# RockChip_RK3588 register map
Vendor: RockChip Electronics Co., Ltd.; Series: RK3588; File version: 0.1
Registers are 32-bit, read-write, no defined reset value unless marked. A register's access mark holds for its fields unless they carry their own. Offsets are from the block's base; [hi:lo] are bit positions; {n}, {i} and the like mark numbered series; 'fields as' and 'values as' point back to an identical list.

## PMU (part 1 of 3)
Base 0xFD8D0000
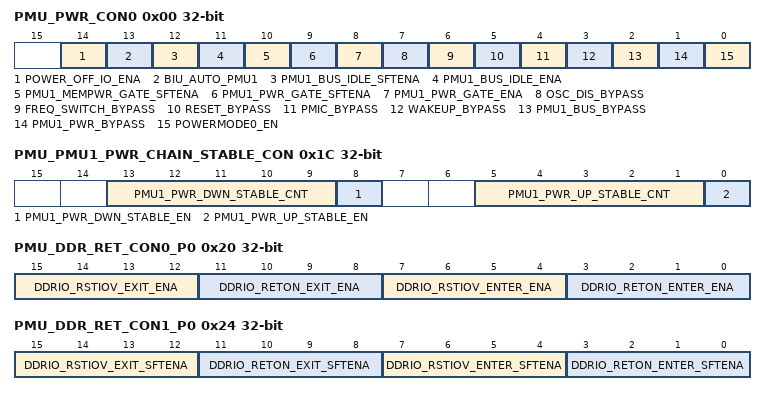
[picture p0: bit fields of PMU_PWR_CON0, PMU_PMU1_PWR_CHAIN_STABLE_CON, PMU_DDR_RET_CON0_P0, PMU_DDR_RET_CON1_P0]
0x00 PMU_PWR_CON0 — PMU power control 0 register
  [all] fields
    0=DISABLE; 1=ENABLE
  [14] POWER_OFF_IO_ENA — Enable VCCIO enter low power mode by hardware.
  [13] BIU_AUTO_PMU1 — When perform idle operation, BIU_PMU1 corresponding clock can be opened or gated automatically.
  [12] PMU1_BUS_IDLE_SFTENA — Enable sending idle request to BIU_PMU1 by software.
  [11] PMU1_BUS_IDLE_ENA — Enable sending idle request to BIU_PMU1 by hardware.
  [10] PMU1_MEMPWR_GATE_SFTENA — Enable power down PD_PMU1's memory by software.
  [9] PMU1_PWR_GATE_SFTENA — Enable power down PD_PMU1 by software.
  [8] PMU1_PWR_GATE_ENA — Enable power down PD_PMU1 by hardware.
  [7] OSC_DIS_BYPASS — Bypass disable oscillator in power mode 0 procedure. If asserted, the oscillator cannot be disabled by FSM during power mode 0 procedure.
  [6] FREQ_SWITCH_BYPASS — Bypass frequency switch stability in power mode 0 procedure. If asserted, clk_pmu cannot be switched to 32KHz clock source during power mode 0 procedure.
  [5] RESET_BYPASS — Bypass wake up reset clear stability in power mode 0 procedure. If asserted, the FSM will enter next state not wait for reset counter, and chip will not be reset.
  [4] PMIC_BYPASS — Bypass waiting for PMIC stability in power mode 0 procedure. If asserted, the FSM will enter next state not wait until PMIC is stable.
  [3] WAKEUP_BYPASS — Bypass waiting for wake up interrupt in power mode 0 procedure. If asserted, the FSM will exit sleep state without waiting for wake up source.
  [2] PMU1_BUS_BYPASS — Bypass BIU_PMU1 idle flow in power mode 0 procedure.
  [1] PMU1_PWR_BYPASS — Bypass PD_PMU1 power gating flow in power mode 0 procedure. If asserted, PD_PMU1 is not power down or power up during power mode 0 procedure.
  [0] POWERMODE0_EN — Power mode 0 enable. When controller enters power mode 0 procedure, this bit is automatically cleared.
0x08 PMU_WAKEUP_INT_CON_P0 — PMU wake up interrupt control register for power mode 0
  [0] WAKEUP_INT_EN — Enable GPIO interrupt as wake up source to exit power mode 0 procedure.
    0=DISABLE; 1=ENABLE
0x0C PMU_WAKEUP_INT_STS_P0 — PMU wake up interrupt status register for power mode 0
  [0] WAKEUP_INT_ST ro — Power mode 0 wake up source status.
    0=INACTIVE; 1=ACTIVE
0x10 PMU_PMIC_STABLE_CNT_P0 — PMIC stable count register for power mode 0
  [19:0] PMIC_STABLE_CNT — PMIC stable count for power mode 0 procedure. Number of clk_pmu used by counter logic.
0x14 PMU_WAKEUP_RST_CLR_CNT_P0 — Wake up reset clear count register for power mode 0
  [19:0] WAKEUP_RST_CLR_CNT — Wake up reset clear count for power mode 0 procedure. Number of clk_pmu used by counter logic.
0x18 PMU_OSC_STABLE_CNT_P0 — Oscillator stable count register for power mode 0
  [19:0] OSC_STABLE_CNT — Oscillator stable count for power mode 0 procedure. Number of clk_pmu used by counter logic.
0x1C PMU_PMU1_PWR_CHAIN_STABLE_CON — PD_PMU1 power chain stable control register
  [13:9] PMU1_PWR_DWN_STABLE_CNT — Stable count for PD_PMU1 power down flow. Number of clk_pmu used by counter logic.
  [8] PMU1_PWR_DWN_STABLE_EN — Enable stable counter between power chains for PD_PMU1 power down flow.
    0=DISABLE; 1=ENABLE
  [5:1] PMU1_PWR_UP_STABLE_CNT — Stable count for PD_PMU1 power up flow. Number of clk_pmu used by counter logic.
  [0] PMU1_PWR_UP_STABLE_EN — Enable stable counter between power chains for PD_PMU1 power up flow.
    0=DISABLE; 1=ENABLE
0x20 PMU_DDR_RET_CON0_P0 — DDR retention control register 0 for power mode 0
  [all] fields
    0=DISABLE; 1=ENABLE
  [15:12] DDRIO_RSTIOV_EXIT_ENA — Enable DDR exits retention mode through RST_IOV by hardware in power mode 0 procedure. Bit[12] used for DDR channel 0. Bit[13] used for DDR channel 1. Bit[14] used for DDR channel 2. Bit[15] used for DDR channel 3.
  [11:8] DDRIO_RETON_EXIT_ENA — Enable DDR exits retention mode through RETON/RETOFF by hardware in power mode 0 procedure. Bit[8] used for DDR channel 0. Bit[9] used for DDR channel 1. Bit[10] used for DDR channel 2. Bit[11] used for DDR channel 3.
  [7:4] DDRIO_RSTIOV_ENTER_ENA — Enable DDR enters retention mode through RST_IOV by hardware in power mode 0 procedure. Bit[4] used for DDR channel 0. Bit[5] used for DDR channel 1. Bit[6] used for DDR channel 2. Bit[7] used for DDR channel 3.
  [3:0] DDRIO_RETON_ENTER_ENA — Enable DDR enters retention mode through RETON/RETOFF by hardware in power mode 0 procedure. Bit[0] used for DDR channel 0. Bit[1] used for DDR channel 1. Bit[2] used for DDR channel 2. Bit[3] used for DDR channel 3.
0x24 PMU_DDR_RET_CON1_P0 — DDR retention control register 1 for power mode 0
  [all] fields
    0=DISABLE; 1=ENABLE
  [15:12] DDRIO_RSTIOV_EXIT_SFTENA — Enable DDR exits retention mode through RST_IOV by software. Bit[12] used for DDR channel 0. Bit[13] used for DDR channel 1. Bit[14] used for DDR channel 2. Bit[15] used for DDR channel 3.
  [11:8] DDRIO_RETON_EXIT_SFTENA — Enable DDR exits retention mode through RETON/RETOFF by software. Bit[8] used for DDR channel 0. Bit[9] used for DDR channel 1. Bit[10] used for DDR channel 2. Bit[11] used for DDR channel 3.
  [7:4] DDRIO_RSTIOV_ENTER_SFTENA — Enable DDR enters retention mode through RST_IOV by software. Bit[4] used for DDR channel 0. Bit[5] used for DDR channel 1. Bit[6] used for DDR channel 2. Bit[7] used for DDR channel 3.
  [3:0] DDRIO_RETON_ENTER_SFTENA — Enable DDR enters retention mode through RETON/RETOFF by software. Bit[0] used for DDR channel 0. Bit[1] used for DDR channel 1. Bit[2] used for DDR channel 2. Bit[3] used for DDR channel 3.
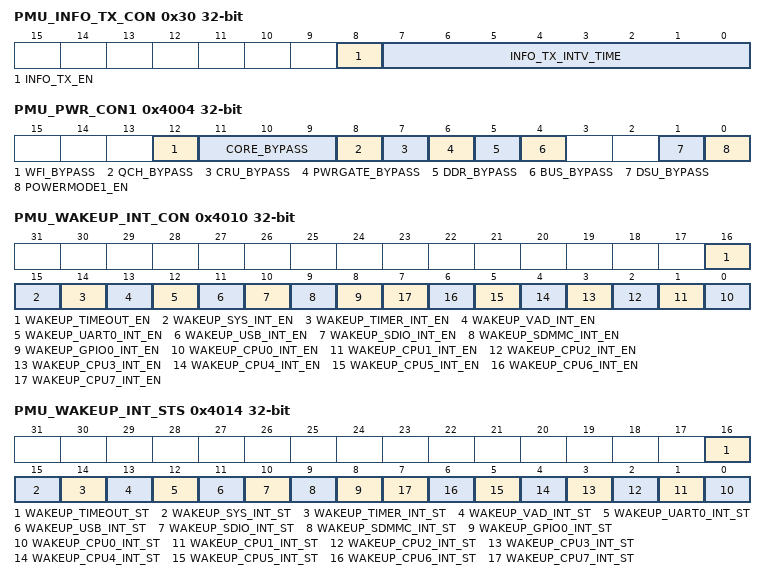
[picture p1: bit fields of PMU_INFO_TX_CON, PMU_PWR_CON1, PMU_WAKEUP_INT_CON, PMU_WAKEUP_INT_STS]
0x30 PMU_INFO_TX_CON — PMU debug information transmit control register
  [8] INFO_TX_EN — Enable PMU debug information transition.
    0=DISABLE; 1=ENABLE
  [7:0] INFO_TX_INTV_TIME — The interval time between the bytes of PMU debug information.
0x4000 PMU_VERSION
  [31:0] VERSION ro
0x4004 PMU_PWR_CON1 — PMU power control 1 register
  [all] fields
    0=DISABLE; 1=ENABLE
  [12] WFI_BYPASS — Bypass WFI in power mode 1 procedure. If asserted, PMU FSM does not need to wait for CPU standbywfi state before entering low power flow.
  [11:9] CORE_BYPASS — Bypass core low power flow in power mode 1 procedure. Bit[9] used to bypass BIGCORE0 low power flow. Bit[10] used to bypass BIGCORE1 low power flow. Bit[11] used to bypass LITDSU low power flow.
  [8] QCH_BYPASS — Bypass power Q-Channel low power flow in power mode 1 procedure. If asserted, PMU_QCHANNEL_PWR_CON cannot take effect for power Q-Channel low power flow. If you want to execute power Q-Channel low power flow, you can program PMU_QCHANNEL_PWR_SFTCON through software flow.
  [7] CRU_BYPASS — Bypass clock and reset low power flow in power mode 1 procedure. If asserted, PMU_CRU_PWR_CON cannot take effect for clock and reset low power flow. If you want to execute clock and reset low power flow, you can program PMU_CRU_PWR_SFTCON through software flow.
  [6] PWRGATE_BYPASS — Bypass power gating flow in power mode 1 procedure. If asserted, PMU_PWR_GATE_CON0/1/2 cannot take effect for power gating flow. If you want to execute power gating flow, you can program PMU_PWR_GATE_SFTCON0/1/2 through software flow.
  [5] DDR_BYPASS — Bypass DDR low power flow in power mode 1 procedure. If asserted, PMU_DDR_CH0/1/2/3_PWR_CON cannot take effect for DDR low power flow. If you want to execute DDR low power flow, you can program PMU_DDR_CH0/1/2/3_PWR_SFTCON through software flow.
  [4] BUS_BYPASS — Bypass BIU idle request in power mode 1 procedure. If asserted, PMU_BIU_IDLE_CON0/1/2 cannot take effect for BIU idle request. If you want to execute BIU idle request, you can program PMU_BIU_IDLE_SFTCON0/1/2 through software flow.
  [1] DSU_BYPASS — Bypass DSU low power flow in power mode 1 procedure.
  [0] POWERMODE1_EN — Power mode 1 enable. When controller enters power mode 1 procedure. It is automatically cleared after PMU enters power mode 1 procedure.
0x4008 PMU_GLB_POWER_STS — PMU global power status register
  [3:0] POWER_STATE ro — PMU1 global power state.
    0=NORMAL (Normal state); 1=CORE_LP (Core low power state); 2=CLUSTER_LP (Cluster low power state); 3=QCH_LP (Q-Channel low power state); 4=BUS_LP (Bus low power state); 5=DDR_LP (DDR low power state); 6=PG_LP (Power gating low power state); 7=CR_LP (Clock and reset low power state); 8=SLEEP (Sleep state); 9=CR_ACTIVE (Clock and reset active state); 10=PG_ACTIVE (Power gating active state); 11=DDR_ACTIVE (DDR active state); 12=BUS_ACTIVE (Bus active state); 13=QCH_ACTIVE (Q-Channel active state); 14=CLUSTER_ACTIVE (Cluster active state); 15=CORE_ACTIVE (Core active state)
0x400C PMU_INT_MASK_CON — PMU interrupt mask control register
  [0] GLB_INT_MASK — Global interrupt mask during DSU sleep state.
    0=UNMASKED (Interrupt is not mask); 1=MASKED (Interrupt is mask)
0x4010 PMU_WAKEUP_INT_CON — PMU wake up interrupt control register
  [all] fields
    0=DISABLE; 1=ENABLE
  [16] WAKEUP_TIMEOUT_EN — Enable PMU wake up timeout as wake up source to exit power mode 1 procedure.
  [15] WAKEUP_SYS_INT_EN — Enable system interrupt as wake up source to exit power mode 1 procedure.
  [14] WAKEUP_TIMER_INT_EN — Enable PMU_TIMER interrupt as wake up source to exit power mode 1 procedure.
  [13] WAKEUP_VAD_INT_EN — Enable VAD interrupt as wake up source to exit power mode 1 procedure.
  [12] WAKEUP_UART0_INT_EN — Enable UART0 interrupt as wake up source to exit power mode 1 procedure.
  [11] WAKEUP_USB_INT_EN — Enable USB detect interrupt as wake up source to exit power mode 1 procedure.
  [10] WAKEUP_SDIO_INT_EN — Enable SDIO interrupt as wake up source to exit power mode 1 procedure.
  [9] WAKEUP_SDMMC_INT_EN — Enable SDMMC detect interrupt as wake up source to exit power mode 1 procedure.
  [8] WAKEUP_GPIO0_INT_EN — Enable GPIO0 interrupt as wake up source to exit power mode 1 procedure.
  [n] WAKEUP_CPU{n}_INT_EN (n=0..7) — Enable CPU{n} interrupt as wake up source to exit power mode 1 procedure.
0x4014 PMU_WAKEUP_INT_STS — PMU wake up interrupt status register
  [all] fields
    0=INACTIVE; 1=ACTIVE
  [16] WAKEUP_TIMEOUT_ST ro — Wake up timeout as wake up source status.
  [15] WAKEUP_SYS_INT_ST ro — System interrupt as wake up source status.
  [14] WAKEUP_TIMER_INT_ST ro — PMU_TIMER interrupt as wake up source status.
  [13] WAKEUP_VAD_INT_ST ro — VAD interrupt as wake up source status.
  [12] WAKEUP_UART0_INT_ST ro — UART0 interrupt as wake up source status.
  [11] WAKEUP_USB_INT_ST ro — USB detect interrupt as wake up source status.
  [10] WAKEUP_SDIO_INT_ST ro — SDIO interrupt as wake up source status.
  [9] WAKEUP_SDMMC_INT_ST ro — SDMMC detect interrupt as wake up source status.
  [8] WAKEUP_GPIO0_INT_ST ro — GPIO0 interrupt as wake up source status.
  [n] WAKEUP_CPU{n}_INT_ST ro (n=0..7) — CPU{n} interrupt as wake up source status.
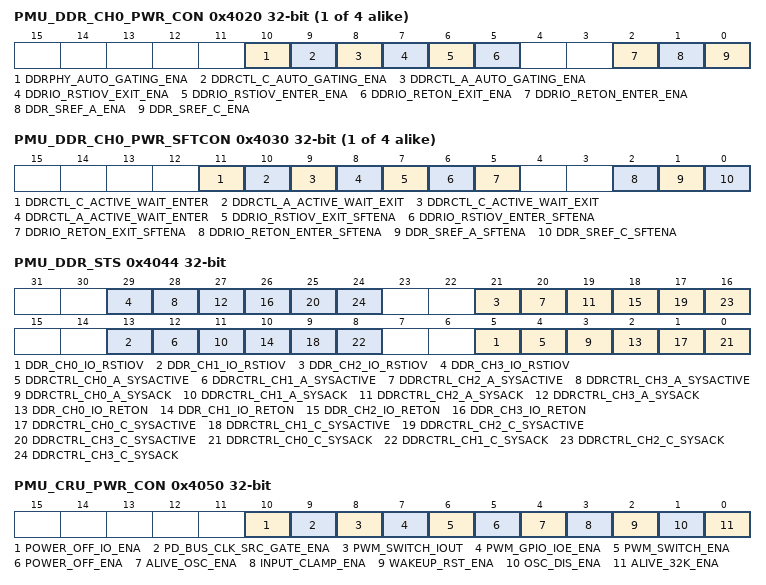
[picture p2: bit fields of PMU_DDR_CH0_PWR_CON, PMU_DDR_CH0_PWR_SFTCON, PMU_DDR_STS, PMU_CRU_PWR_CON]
{0x4020+4i} PMU_DDR_CH{i}_PWR_CON (i=0..3) — DDR channel {i} hardware power control register
  [all] fields
    0=DISABLE; 1=ENABLE
  [10] DDRPHY_AUTO_GATING_ENA — Enable DDRPHY auto clock gating. DDRPHY's clock can be gated when in sleep mode.
  [9] DDRCTL_C_AUTO_GATING_ENA — Enable DDRCTRL's core-clock auto clock gating. Core-clock can be gated when in self-refresh mode.
  [8] DDRCTL_A_AUTO_GATING_ENA — Enable DDRCTRL's AXI-clock auto clock gating. AXI-clock can be gated when in self-refresh mode.
  [7] DDRIO_RSTIOV_EXIT_ENA — Enable DDR exits retention mode through RST_IOV by hardware.
  [6] DDRIO_RSTIOV_ENTER_ENA — Enable DDR enters retention mode through RST_IOV by hardware.
  [5] DDRIO_RETON_EXIT_ENA — Enable DDR exits retention mode through RETON/RETOFF by hardware.
  [2] DDRIO_RETON_ENTER_ENA — Enable DDR enters retention mode through RETON/RETOFF by hardware.
  [1] DDR_SREF_A_ENA — Enable DDR self-refresh mode for AXI-clock domain by hardware.
  [0] DDR_SREF_C_ENA — Enable DDR self-refresh mode for core-clock domain by hardware.
{0x4030+4i} PMU_DDR_CH{i}_PWR_SFTCON (i=0..3) — DDR channel {i} software power control register
  [11] DDRCTL_C_ACTIVE_WAIT_ENTER
    0=NOT_NEED (Not need to wait for ddrctl_c_active low before FSM enter self-refresh state); 1=NEED (Need to wait for ddrctl_c_active low before FSM enter self- refresh state)
  [10] DDRCTL_A_ACTIVE_WAIT_EXIT
    0=NOT_NEED (Not need to wait for ddrctl_a_active high before FSM exit self-refresh state); 1=NEED (Need to wait for ddrctl_a_active high before FSM exit self- refresh state)
  [9] DDRCTL_C_ACTIVE_WAIT_EXIT
    0=NOT_NEED (Not need to wait for ddrctl_c_active high before FSM exit self-refresh state); 1=NEED (Need to wait for ddrctl_c_active high before FSM exit self- refresh state)
  [8] DDRCTL_A_ACTIVE_WAIT_ENTER
    0=NOT_NEED (Not need to wait for ddrctl_a_active low before FSM enter self-refresh state); 1=NEED (Need to wait for ddrctl_a_active low before FSM enter self- refresh state)
  [7] DDRIO_RSTIOV_EXIT_SFTENA — Enable DDR exits retention mode through RST_IOV by software. It is auto cleared after DDR exits retention mode.
    0=DISABLE; 1=ENABLE
  [6] DDRIO_RSTIOV_ENTER_SFTENA — Enable DDR enters retention mode through RST_IOV by software.
    0=DISABLE; 1=ENABLE
  [5] DDRIO_RETON_EXIT_SFTENA — Enable DDR exits retention mode through RETON/RETOFF by software. It is auto cleared after DDR exits retention mode.
    0=DISABLE; 1=ENABLE
  [2] DDRIO_RETON_ENTER_SFTENA — Enable DDR enters retention mode through RETON/RETOFF by software.
    0=DISABLE; 1=ENABLE
  [1] DDR_SREF_A_SFTENA — Enable DDR self-refresh mode for AXI-clock domain by software.
    0=DISABLE; 1=ENABLE
  [0] DDR_SREF_C_SFTENA — Enable DDR self-refresh mode for core-clock domain by software.
    0=DISABLE; 1=ENABLE
0x4040 PMU_DDR_POWER_STS — DDR power state register
  [3:0] DDR_POWER_STATE ro
    0=Normal state; 1=Enter self-refresh mode for AXI-clock state; 2=Enter self-refresh mode core-clock state; 3=Enter retention mode through RETON/RETOFF state; 4=Enter retention mode through RST_IOV state; 5=Sleep state; 6=Exit retention mode through RST_IOV state; 7=Exit retention mode through RETON/RETOFF state; 8=Exit self-refresh mode for core-clock state; 9=Exit self-refresh mode for AXI-clock state Others: Reserved
0x4044 PMU_DDR_STS — DDR state register
  [all] fields
    0=INACTIVE; 1=ACTIVE
  [8n+5] DDR_CH{n}_IO_RSTIOV ro (n=0..3) — DDR RST_IOV state for channel {n}.
  [8n+4] DDRCTRL_CH{n}_A_SYSACTIVE ro (n=0..3) — DDRC AXI clock active for channel {n}.
  [8n+3] DDRCTRL_CH{n}_A_SYSACK ro (n=0..3) — DDRC AXI hardware low-power request acknowledge for channel {n}.
  [8n+2] DDR_CH{n}_IO_RETON ro (n=0..3) — DDR RETON/RETOFF state for channel {n}.
  [8n+1] DDRCTRL_CH{n}_C_SYSACTIVE ro (n=0..3) — DDRC hardware low-power clock active for channel {n}.
  [8n] DDRCTRL_CH{n}_C_SYSACK ro (n=0..3) — DDRC hardware low-power request acknowledge for channel {n}.
0x4050 PMU_CRU_PWR_CON — Clock and reset hardware power control register
  [10] POWER_OFF_IO_ENA — Enable VCCIO enter low power mode by hardware.
    0=DISABLE; 1=ENABLE
  [9] PD_BUS_CLK_SRC_GATE_ENA — Gating BIU_BUS's clock source during clock low power mode.
    0=DISABLE; 1=ENABLE
  [8] PWM_SWITCH_IOUT — PWM output.
    0=DISABLE; 1=ENABLE (It is set 0 for RK3588.)
  [7] PWM_GPIO_IOE_ENA — PWM output enable.
    0=DISABLE; 1=ENABLE (` It is set 0 for RK3588.)
  [6] PWM_SWITCH_ENA — PWM switch enable.
    0=DISABLE; 1=ENABLE (` It is set 0 for RK3588.)
  [5] POWER_OFF_ENA — Enable chip power off by hardware.
    0=DISABLE; 1=ENABLE
  [4] ALIVE_OSC_ENA — Enable clk_pmu/hclk_pmu/pclk_pmu switch to oscillator by hardware. When alive_32k_ena is asserted, this bit is ignored.
    0=DISABLE; 1=ENABLE
  [3] INPUT_CLAMP_ENA — Enable VD_PMU input clamped by hardware.
    0=DISABLE; 1=ENABLE
  [2] WAKEUP_RST_ENA — Enable wake up reset by hardware. If asserted, all registers without reset hold will be reset after chip wake up.
    0=DISABLE; 1=ENABLE
  [1] OSC_DIS_ENA — Disable oscillator by hardware.
    0=ENABLE; 1=DISABLE
  [0] ALIVE_32K_ENA — Enable pclk_pmu and clk_pmu switch to 32KHz clock by hardware.
    0=DISABLE; 1=ENABLE
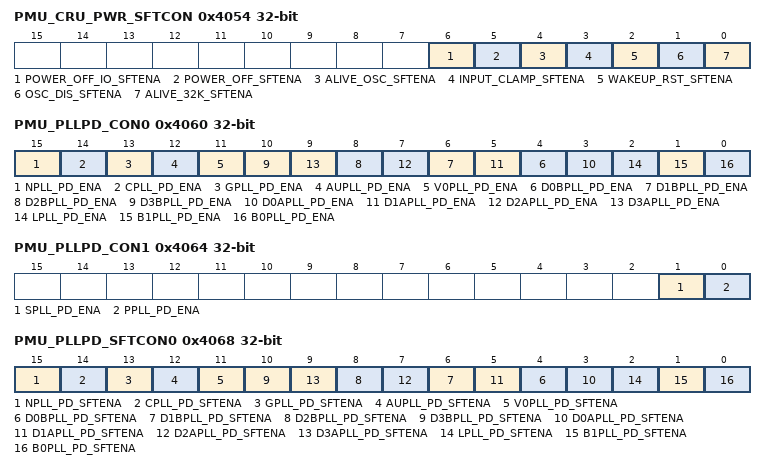
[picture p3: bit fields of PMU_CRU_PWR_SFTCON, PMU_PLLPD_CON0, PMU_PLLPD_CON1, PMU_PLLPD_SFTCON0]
0x4054 PMU_CRU_PWR_SFTCON — Clock and reset software power control register
  [6] POWER_OFF_IO_SFTENA — Enable VCCIO enter low power mode by software.
    0=DISABLE; 1=ENABLE
  [5] POWER_OFF_SFTENA — Enable chip power off by software.
    0=DISABLE; 1=ENABLE
  [4] ALIVE_OSC_SFTENA — Enable clk_pmu/hclk_pmu/pclk_pmu switch to oscillator by software. When alive_32k_ena is asserted, this bit is ignored.
    0=DISABLE; 1=ENABLE
  [3] INPUT_CLAMP_SFTENA — Enable VD_PMU input clamp by software.
    0=DISABLE; 1=ENABLE
  [2] WAKEUP_RST_SFTENA — Enable wake up reset by software. If asserted, all digital except IP with reset hold will be reset.
    0=DISABLE; 1=ENABLE
  [1] OSC_DIS_SFTENA — Disable oscillator by software.
    0=ENABLE; 1=DISABLE
  [0] ALIVE_32K_SFTENA — Enable pclk_pmu and clk_pmu switch to 32KHz clock by software.
    0=DISABLE; 1=ENABLE
0x4058 PMU_CRU_POWER_STS — Clock and reset power state register
  [3:0] CRU_POWER_STATE ro — Clock and reset power state.
    0=Normal state; 1=Clock low frequency state; 2=PLL power down state; 3=Input clamp state; 4=Oscillator disable state; 5=Sleep state; 6=Wake up state; 7=Input clamp release state; 8=Oscillator enable state; 9=Clock high frequency state; 10=Wake up reset clear state; 12=PLL power up state Others: Reserved
0x4060 PMU_PLLPD_CON0 — PLL hardware power control register 0
  [all] fields
    0=DISABLE; 1=ENABLE
  [15] NPLL_PD_ENA — Enable power down NPLL by hardware.
  [14] CPLL_PD_ENA — Enable power down CPLL by hardware.
  [13] GPLL_PD_ENA — Enable power down GPLL by hardware.
  [12] AUPLL_PD_ENA — Enable power down AUPLL by hardware.
  [11] V0PLL_PD_ENA — Enable power down V0PLL by hardware.
  [2n+4] D{n}BPLL_PD_ENA (n=0..3) — Enable power down D{n}BPLL by hardware.
  [2n+3] D{n}APLL_PD_ENA (n=0..3) — Enable power down D{n}APLL by hardware.
  [2] LPLL_PD_ENA — Enable power down LPLL by hardware.
  [1] B1PLL_PD_ENA — Enable power down B1PLL by hardware.
  [0] B0PLL_PD_ENA — Enable power down B0PLL by hardware.
0x4064 PMU_PLLPD_CON1 — PLL hardware power control register 1
  [1] SPLL_PD_ENA — Enable power down SPLL by hardware.
    0=DISABLE; 1=ENABLE
  [0] PPLL_PD_ENA — Enable power down PPLL by hardware.
    0=DISABLE; 1=ENABLE
0x4068 PMU_PLLPD_SFTCON0 — PLL software power control register 0
  [all] fields
    0=DISABLE; 1=ENABLE
  [15] NPLL_PD_SFTENA — Enable power down NPLL by software.
  [14] CPLL_PD_SFTENA — Enable power down CPLL by software.
  [13] GPLL_PD_SFTENA — Enable power down GPLL by software.
  [12] AUPLL_PD_SFTENA — Enable power down AUPLL by software.
  [11] V0PLL_PD_SFTENA — Enable power down V0PLL by software.
  [2n+4] D{n}BPLL_PD_SFTENA (n=0..3) — Enable power down D{n}BPLL by software.
  [2n+3] D{n}APLL_PD_SFTENA (n=0..3) — Enable power down D{n}APLL by software.
  [2] LPLL_PD_SFTENA — Enable power down LPLL by software.
  [1] B1PLL_PD_SFTENA — Enable power down B1PLL by software.
  [0] B0PLL_PD_SFTENA — Enable power down B0PLL by software.
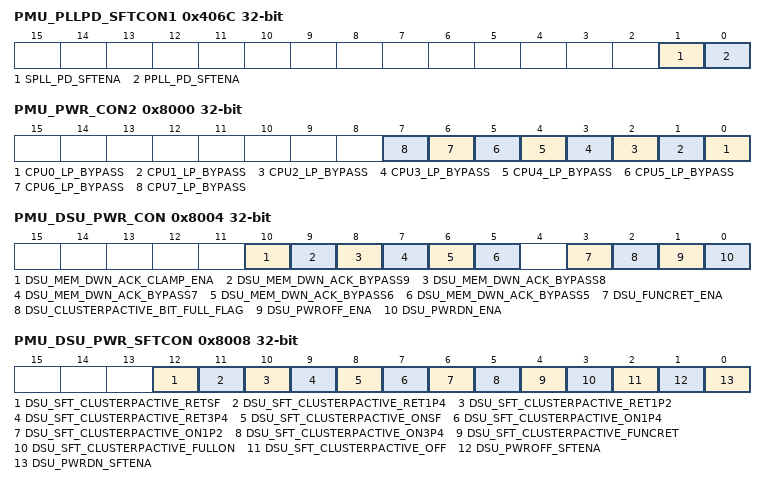
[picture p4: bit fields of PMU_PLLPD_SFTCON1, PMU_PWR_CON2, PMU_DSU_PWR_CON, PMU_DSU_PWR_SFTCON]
0x406C PMU_PLLPD_SFTCON1 — PLL software power control register 1
  [1] SPLL_PD_SFTENA — Enable power down SPLL by software.
    0=DISABLE; 1=ENABLE
  [0] PPLL_PD_SFTENA — Enable power down PPLL by software.
    0=DISABLE; 1=ENABLE
0x4080 PMU_PMIC_STABLE_CNT — PMIC stable count register
  [19:0] PMIC_STABLE_CNT — PMIC stable count for mode 1 procedure. Number of clk_pmu used by counter logic.
0x4084 PMU_OSC_STABLE_CNT — Oscillator stable count register
  [19:0] OSC_STABLE_CNT — Oscillator stable count for mode 1 procedure. Number of clk_pmu used by counter logic.
0x4088 PMU_WAKEUP_RST_CLR_ CNT — Wake up reset clear count register
  [19:0] WAKEUP_RST_CLR_CNT — Wake up reset clear count for mode 1 procedure. Number of clk_pmu used by counter logic.
0x408C PMU_PLL_LOCK_CNT — PLL lock count register
  [19:0] PLL_LOCK_CNT — Count for PLL from power up to lock. Number of clk_pmu used by counter logic.
0x4094 PMU_WAKEUP_TIMEOUT_ CNT — PMU wake up timeout count register
  [19:0] WAKEUP_TIMEOUT_CNT — Wake up timeout count. Number of clk_pmu used by counter logic.
0x4098 PMU_PWM_SWITCH_CNT — PWM switch stable count register
  [19:0] PWM_SWITCH_CNT — PWM switch count. Number of clk_pmu used by counter logic.
{0x4100+4i} PMU_SYS_REG{i} (i=0..7) — PMU system register {i}. It cannot be reset by software.
0x8000 PMU_PWR_CON2 — PMU hardware power control 2 register
  [all] fields
    0=DISABLE; 1=ENABLE
  [n] CPU{n}_LP_BYPASS (n=0..7) — Bypass CPU{n} low power flow.
0x8004 PMU_DSU_PWR_CON — DSU hardware power control register
  [10] DSU_MEM_DWN_ACK_CLAMP_ENA — Enable clamp for VD_DSU memory power down acknowledge. This bit should be set to 1 if dsu_pwroff_ena=1 and VD_DSU will be power off.
    0=DISABLE; 1=ENABLE
  [9] DSU_MEM_DWN_ACK_BYPASS9 — used to bypass other memory power down acknowledge. If memory is power down before DSU enter power down mode, you should set relative bypass bit high.
    0=DISABLE; 1=ENABLE
  [8] DSU_MEM_DWN_ACK_BYPASS8 — used to bypass "L3 Tag ways 8~11, L3 Data portion 1 RAMs" memory power down acknowledge.
    0=DISABLE; 1=ENABLE
  [7] DSU_MEM_DWN_ACK_BYPASS7 — used to bypass "L3 Tag ways 4~7" memory power down acknowledge.
    0=DISABLE; 1=ENABLE
  [6] DSU_MEM_DWN_ACK_BYPASS6 — used to bypass "L3 Tag ways 0~3, L3 Data portion 0, and L3 Victim RAMs" memory power down acknowledge.
    0=DISABLE; 1=ENABLE
  [5] DSU_MEM_DWN_ACK_BYPASS5 — used to bypass "Snoop filter and LTDB RAMs" memory power down acknowledge.
    0=DISABLE; 1=ENABLE
  [3] DSU_FUNCRET_ENA — Enable DSU FUNC_RET mode by hardware.
    0=DISABLE; 1=ENABLE
  [2] DSU_CLUSTERPACTIVE_BIT_FULL_FLAG — CLUSTERPACTIVE bit full flag. If DSU power mode wants to transfer from any mode to FULL ON or FULL FUNC_RET, this bit should be set to 1. Otherwise, this bit should be set to 0.
  [1] DSU_PWROFF_ENA — Enable VD_LITDSU power off by hardware. If you just power down VD_LITDSU memory but not power off VD_LITDSU, this bit should be set to 0. If you want to power off VD_LITDSU by hardware, this bit should be set to 1.
    0=DISABLE; 1=ENABLE
  [0] DSU_PWRDN_ENA — Enable VD_LITDSU power down by hardware.
    0=DISABLE; 1=ENABLE
0x8008 PMU_DSU_PWR_SFTCON — DSU software power control register
  [12] DSU_SFT_CLUSTERPACTIVE_RETSF — CLUSTERPACTIVE bit generated by software when requested mode is SFONLY FUNC_RET mode. High active. It is auto cleared when CLUSTERPREQ is active. It is used when DSU power mode transition is controlled by software.
    1=ACTIVE
  [11] DSU_SFT_CLUSTERPACTIVE_RET1P4 — CLUSTERPACTIVE bit generated by software when requested mode is 1/4 FUNC_RET mode. High active. It is auto cleared when CLUSTERPREQ is active. It is used when DSU power mode transition is controlled by software.
    1=ACTIVE
  [10] DSU_SFT_CLUSTERPACTIVE_RET1P2 — CLUSTERPACTIVE bit generated by software when requested mode is 1/2 FUNC_RET mode. High active. It is auto cleared when CLUSTERPREQ is active. It is used when DSU power mode transition is controlled by software.
    1=ACTIVE
  [9] DSU_SFT_CLUSTERPACTIVE_RET3P4 — CLUSTERPACTIVE bit generated by software when requested mode is 3/4 FUNC_RET mode. High active. It is auto cleared when CLUSTERPREQ is active. It is used when DSU power mode transition is controlled by software.
    1=ACTIVE
  [8] DSU_SFT_CLUSTERPACTIVE_ONSF — CLUSTERPACTIVE bit generated by software when requested mode is SFONLY ON mode. High active. It is auto cleared when CLUSTERPREQ is active. It is used when DSU power mode transition is controlled by software.
    1=ACTIVE
  [7] DSU_SFT_CLUSTERPACTIVE_ON1P4 — CLUSTERPACTIVE bit generated by software when requested mode is 1/4 ON mode. High active. It is auto cleared when CLUSTERPREQ is active. It is used when DSU power mode transition is controlled by software.
    1=ACTIVE
  [6] DSU_SFT_CLUSTERPACTIVE_ON1P2 — CLUSTERPACTIVE bit generated by software when requested mode is 1/2 ON mode. High active. It is auto cleared when CLUSTERPREQ is active. It is used when DSU power mode transition is controlled by software.
    1=ACTIVE
  [5] DSU_SFT_CLUSTERPACTIVE_ON3P4 — CLUSTERPACTIVE bit generated by software when requested mode is 3/4 ON mode. High active. It is auto cleared when CLUSTERPREQ is active. It is used when DSU power mode transition is controlled by software.
    1=ACTIVE
  [4] DSU_SFT_CLUSTERPACTIVE_FUNCRET — CLUSTERPACTIVE bit generated by software when requested mode is FUNC_RET mode. High active. It is auto cleared when CLUSTERPREQ is active. It is used when DSU power mode transition is controlled by software.
    1=ACTIVE
  [3] DSU_SFT_CLUSTERPACTIVE_FULLON — CLUSTERPACTIVE bit generated by software when requested mode is FULL ON mode. High active. It is auto cleared when CLUSTERPREQ is active. It is used when DSU power mode transition is controlled by software.
    1=ACTIVE
  [2] DSU_SFT_CLUSTERPACTIVE_OFF — CLUSTERPACTIVE bit generated by software when requested mode is OFF mode. High active. It is auto cleared when CLUSTERPREQ is active. It is used when DSU power mode transition is controlled by software.
    1=ACTIVE
  [1] DSU_PWROFF_SFTENA — Enable VD_LITDSU power off by software.
    0=DISABLE; 1=ENABLE
  [0] DSU_PWRDN_SFTENA — Enable VD_LITDSU power down by software.
    0=DISABLE; 1=ENABLE
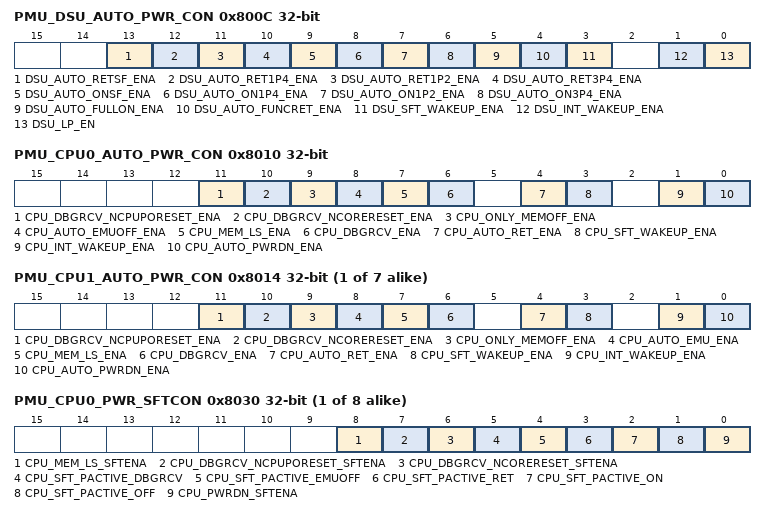
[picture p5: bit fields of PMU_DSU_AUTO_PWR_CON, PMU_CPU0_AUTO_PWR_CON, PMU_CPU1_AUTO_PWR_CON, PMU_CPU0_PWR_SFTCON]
0x800C PMU_DSU_AUTO_PWR_CON — DSU automatic power control register
  [13] DSU_AUTO_RETSF_ENA — Enable DSU enters SFONLY FUNC_RET mode automatically.
    0=DISABLE; 1=ENABLE
  [12] DSU_AUTO_RET1P4_ENA — Enable DSU enters 1/4 FUNC_RET mode automatically.
    0=DISABLE; 1=ENABLE
  [11] DSU_AUTO_RET1P2_ENA — Enable DSU enters 1/2 FUNC_RET mode automatically.
    0=DISABLE; 1=ENABLE
  [10] DSU_AUTO_RET3P4_ENA — Enable DSU enters 3/4 FUNC_RET mode automatically.
    0=DISABLE; 1=ENABLE
  [9] DSU_AUTO_ONSF_ENA — Enable DSU enters SFONLY ON mode automatically.
    0=DISABLE; 1=ENABLE
  [8] DSU_AUTO_ON1P4_ENA — Enable DSU enters 1/4 ON mode automatically.
    0=DISABLE; 1=ENABLE
  [7] DSU_AUTO_ON1P2_ENA — Enable DSU enters 1/2 ON mode automatically.
    0=DISABLE; 1=ENABLE
  [6] DSU_AUTO_ON3P4_ENA — Enable DSU enters 3/4 ON mode automatically.
    0=DISABLE; 1=ENABLE
  [5] DSU_AUTO_FULLON_ENA — Enable DSU enters FULL ON mode automatically.
    0=DISABLE; 1=ENABLE
  [4] DSU_AUTO_FUNCRET_ENA — Enable DSU enters FUNC_RET mode automatically.
    0=DISABLE; 1=ENABLE
  [3] DSU_SFT_WAKEUP_ENA — Enable VD_LITDSU wake up by software.
    0=INACTIVE (Wake up source inactive); 1=ACTIVE (Wake up source active)
  [1] DSU_INT_WAKEUP_ENA — Enable interrupt as VD_LITDSU wake up source.
    0=DISABLE; 1=ENABLE
  [0] DSU_LP_EN — Enable VD_LITDSU low power mode.
    0=DISABLE; 1=ENABLE
0x8010 PMU_CPU0_AUTO_PWR_CON — CPU0 automatic power control register
  [11] CPU_DBGRCV_NCPUPORESET_ENA — Enable CPU enters cold reset by assert ncpureset when CPU in debug recovery mode by hardware.
    0=DISABLE; 1=ENABLE
  [10] CPU_DBGRCV_NCORERESET_ENA — Enable CPU enters warm reset by assert ncorereset when CPU in debug recovery mode by hardware.
    0=DISABLE; 1=ENABLE
  [9] CPU_ONLY_MEMOFF_ENA — Enable only power down CPU memory. i.e., just power down memory, but not other digital logic when CPU in OFF mode.
    0=DISABLE; 1=ENABLE
  [8] CPU_AUTO_EMUOFF_ENA — Enable CPU emulated off mode by hardware.
    0=DISABLE; 1=ENABLE
  [7] CPU_MEM_LS_ENA — Enable CPU memory light sleep mode by hardware.
    0=DISABLE; 1=ENABLE
  [6] CPU_DBGRCV_ENA — Enable CPU debug recovery mode by hardware. It is auto cleared when FSM enters debug recovery state.
    0=DISABLE; 1=ENABLE
  [4] CPU_AUTO_RET_ENA — Enable CPU retention mode by hardware.
    0=DISABLE; 1=ENABLE
  [3] CPU_SFT_WAKEUP_ENA — Enable CPU wake up by software.
    values as PMU_DSU_AUTO_PWR_CON.DSU_SFT_WAKEUP_ENA
  [1] CPU_INT_WAKEUP_ENA — Enable interrupt as CPU wake up source.
    0=DISABLE; 1=ENABLE
  [0] CPU_AUTO_PWRDN_ENA — Enable CPU power down automatically.
    0=DISABLE; 1=ENABLE
{0x8010+4i} PMU_CPU{i}_AUTO_PWR_CON (i=1..7) — CPU{i} automatic power control register
  [11] CPU_DBGRCV_NCPUPORESET_ENA — Enable CPU enters cold reset by assert ncpureset when CPU in debug recovery mode by hardware.
    0=DISABLE; 1=ENABLE
  [10] CPU_DBGRCV_NCORERESET_ENA — Enable CPU enters warm reset by assert ncorereset when CPU in debug recovery mode by hardware.
    0=DISABLE; 1=ENABLE
  [9] CPU_ONLY_MEMOFF_ENA — Enable only power down CPU memory. i.e., just power down memory, but not other digital logic when CPU in OFF mode.
    0=DISABLE; 1=ENABLE
  [8] CPU_AUTO_EMU_ENA — Enable CPU emulated off mode by hardware.
    0=DISABLE; 1=ENABLE
  [7] CPU_MEM_LS_ENA — Enable CPU memory light sleep mode by hardware.
    0=DISABLE; 1=ENABLE
  [6] CPU_DBGRCV_ENA — Enable CPU debug recovery mode by hardware. It is auto cleared when FSM enters debug recovery state.
    0=DISABLE; 1=ENABLE
  [4] CPU_AUTO_RET_ENA — Enable CPU retention mode by hardware.
    0=DISABLE; 1=ENABLE
  [3] CPU_SFT_WAKEUP_ENA — Enable CPU wake up by software.
    values as PMU_DSU_AUTO_PWR_CON.DSU_SFT_WAKEUP_ENA
  [1] CPU_INT_WAKEUP_ENA — Enable interrupt as CPU wake up source.
    0=DISABLE; 1=ENABLE
  [0] CPU_AUTO_PWRDN_ENA — Enable CPU power down automatically.
    0=DISABLE; 1=ENABLE
{0x8030+4i} PMU_CPU{i}_PWR_SFTCON (i=0..7) — CPU{i} software power control register
  [8] CPU_MEM_LS_SFTENA — Enable CPU memory light sleep mode by software.
    0=DISABLE; 1=ENABLE
  [7] CPU_DBGRCV_NCPUPORESET_SFTENA — Enable CPU enters cold reset by assert ncpureset when CPU in debug recovery mode by software.
    0=ENABLE; 1=DISABLE
  [6] CPU_DBGRCV_NCORERESET_SFTENA — Enable CPU enters warm reset by assert ncorereset when CPU in debug recovery mode by software.
    0=ENABLE; 1=DISABLE
  [5] CPU_SFT_PACTIVE_DBGRCV — PACTIVE bit generated by software when requested mode is debug recovery mode. High active. It is auto cleared when PREQ is active. It is used when CPU power mode transition is controlled by software.
    1=ACTIVE
  [4] CPU_SFT_PACTIVE_EMUOFF — PACTIVE bit generated by software when requested mode is emulated off mode. High active. It is auto cleared when PREQ is active. It is used when CPU power mode transition is controlled by software.
    1=ACTIVE
  [3] CPU_SFT_PACTIVE_RET — PACTIVE bit generated by software when requested mode is retention mode. High active. It is auto cleared when PREQ is active. It is used when CPU power mode transition is controlled by software.
    1=ACTIVE
  [2] CPU_SFT_PACTIVE_ON — PACTIVE bit generated by software when requested mode is ON mode. High active. It is auto cleared when PREQ is active. It is used when CPU power mode transition is controlled by software.
    1=ACTIVE
  [1] CPU_SFT_PACTIVE_OFF — PACTIVE bit generated by software when requested mode is OFF mode. High active. It is auto cleared when PREQ is active. It is used when CPU power mode transition is controlled by software.
    1=ACTIVE
  [0] CPU_PWRDN_SFTENA — Enable CPU power down by software.
    0=DISABLE; 1=ENABLE
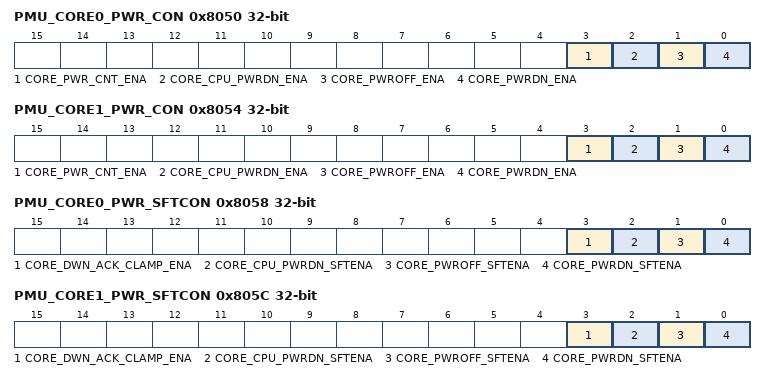
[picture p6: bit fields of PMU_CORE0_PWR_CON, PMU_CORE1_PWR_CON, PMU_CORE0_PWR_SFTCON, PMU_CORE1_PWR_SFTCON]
0x8050 PMU_CORE0_PWR_CON — BIGCORE0 hardware power control register
  [all] fields
    0=DISABLE; 1=ENABLE
  [3] CORE_PWR_CNT_ENA — Enable counter to wait for VD_BIGCORE0 power on or power off stability.
  [2] CORE_CPU_PWRDN_ENA — Enable CPU power down when VD_BIGCORE0 power down by hardware.
  [1] CORE_PWROFF_ENA — Enable VD_BIGCORE0 power off by hardware.
  [0] CORE_PWRDN_ENA — Enable VD_BIGCORE0 power down by hardware.
0x8054 PMU_CORE1_PWR_CON — BIGCORE1 hardware power control register
  [all] fields
    0=DISABLE; 1=ENABLE
  [3] CORE_PWR_CNT_ENA — Enable counter to wait for VD_BIGCORE1 power on or power off stability.
  [2] CORE_CPU_PWRDN_ENA — Enable CPU power down when VD_BIGCORE1 power down by hardware.
  [1] CORE_PWROFF_ENA — Enable VD_BIGCORE1 power off by hardware.
  [0] CORE_PWRDN_ENA — Enable VD_BIGCORE1 power down by hardware.
0x8058 PMU_CORE0_PWR_SFTCON — BIGCORE0 software power control register
  [all] fields
    0=DISABLE; 1=ENABLE
  [3] CORE_DWN_ACK_CLAMP_ENA — Enable clamp for VD_BIGCORE0 power down acknowledge. This bit should be set to 1 if VD_BIGCORE0 power off.
  [2] CORE_CPU_PWRDN_SFTENA — Enable CPU power down when VD_BIGCORE0 power down by software.
  [1] CORE_PWROFF_SFTENA — Enable VD_BIGCORE0 power off by software.
  [0] CORE_PWRDN_SFTENA — Enable VD_BIGCORE0 power down by software.
0x805C PMU_CORE1_PWR_SFTCON — BIGCORE1 software power control register
  [all] fields
    0=DISABLE; 1=ENABLE
  [3] CORE_DWN_ACK_CLAMP_ENA — Enable clamp for VD_BIGCORE1 power down acknowledge. This bit should be set to 1 if VD_BIGCORE1 power off.
  [2] CORE_CPU_PWRDN_SFTENA — Enable CPU power down when VD_BIGCORE1 power down by software.
  [1] CORE_PWROFF_SFTENA — Enable VD_BIGCORE1 power off by software.
  [0] CORE_PWRDN_SFTENA — Enable VD_BIGCORE1 power down by software.
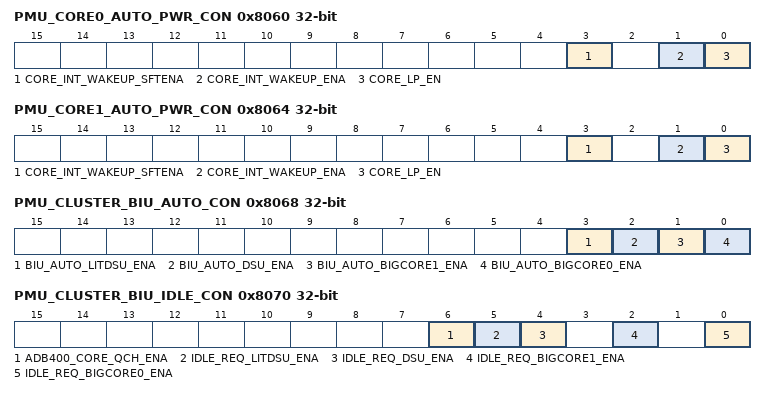
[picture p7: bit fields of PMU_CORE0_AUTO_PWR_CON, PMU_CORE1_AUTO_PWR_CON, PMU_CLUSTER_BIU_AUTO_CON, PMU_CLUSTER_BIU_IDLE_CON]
0x8060 PMU_CORE0_AUTO_PWR_CON — BIGCORE0 automatic power control register
  [3] CORE_INT_WAKEUP_SFTENA — Enable VD_BIGCORE0 wake up by software.
    values as PMU_DSU_AUTO_PWR_CON.DSU_SFT_WAKEUP_ENA
  [1] CORE_INT_WAKEUP_ENA — Enable interrupt as VD_BIGCORE0 wake up source.
    0=DISABLE; 1=ENABLE
  [0] CORE_LP_EN — Enable VD_BIGCORE0 low power mode.
    0=DISABLE; 1=ENABLE
0x8064 PMU_CORE1_AUTO_PWR_CON — BIGCORE1 automatic power control register
  [3] CORE_INT_WAKEUP_SFTENA — Enable VD_BIGCORE1 wake up by software.
    values as PMU_DSU_AUTO_PWR_CON.DSU_SFT_WAKEUP_ENA
  [1] CORE_INT_WAKEUP_ENA — Enable interrupt as VD_BIGCORE1 wake up source.
    0=DISABLE; 1=ENABLE
  [0] CORE_LP_EN — Enable VD_BIGCORE1 low power mode.
    0=DISABLE; 1=ENABLE
0x8068 PMU_CLUSTER_BIU_AUTO_CON — Cluster BIU automatic power control register
  [all] fields
    0=DISABLE; 1=ENABLE
  [3] BIU_AUTO_LITDSU_ENA — If enable, BIU_LITDSU corresponding clock can be opened or gated automatically when idle operation.
  [2] BIU_AUTO_DSU_ENA — If enable, BIU_DSU corresponding clock can be opened or gated automatically when idle operation.
  [1] BIU_AUTO_BIGCORE1_ENA — If enable, BIU_BIGCORE1 corresponding clock can be opened or gated automatically when idle operation.
  [0] BIU_AUTO_BIGCORE0_ENA — If enable, BIU_BIGCORE0 corresponding clock can be opened or gated automatically when idle operation.
0x8070 PMU_CLUSTER_BIU_IDLE_CON — Cluster BIU idle request hardware control register
  [all] fields
    0=DISABLE; 1=ENABLE
  [6] ADB400_CORE_QCH_ENA — Enable core ADB400 Q-Channel power control by hardware.
  [5] IDLE_REQ_LITDSU_ENA — Enable sending idle request to BIU_LITDSU by hardware.
  [4] IDLE_REQ_DSU_ENA — Enable sending idle request to BIU_DSU by hardware.
  [2] IDLE_REQ_BIGCORE1_ENA — Enable sending idle request to BIU_BIGCORE1 by hardware.
  [0] IDLE_REQ_BIGCORE0_ENA — Enable sending idle request to BIU_BIGCORE0 by hardware.
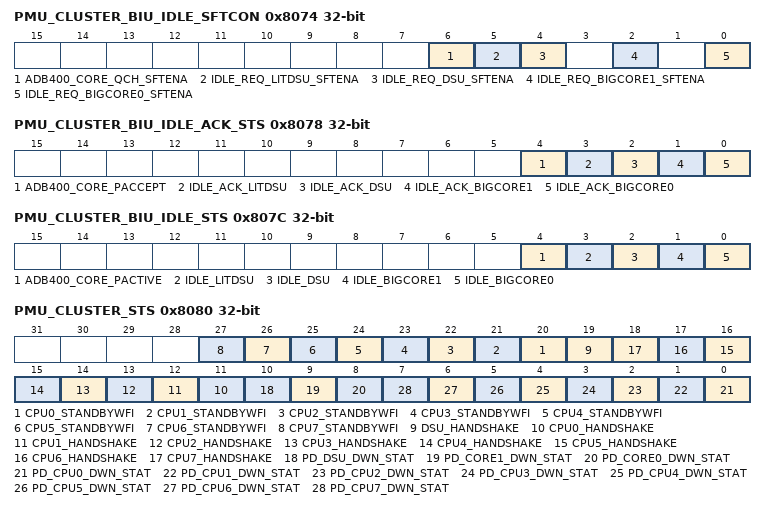
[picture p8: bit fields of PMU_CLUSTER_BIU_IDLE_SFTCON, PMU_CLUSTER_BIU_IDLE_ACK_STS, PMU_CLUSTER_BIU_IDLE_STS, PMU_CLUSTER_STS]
0x8074 PMU_CLUSTER_BIU_IDLE_SFTCON — Cluster BIU idle request software control register
  [all] fields
    0=DISABLE; 1=ENABLE
  [6] ADB400_CORE_QCH_SFTENA — Enable core ADB400 Q-Channel power control by software.
  [5] IDLE_REQ_LITDSU_SFTENA — Enable sending idle request to BIU_LITDSU by software.
  [4] IDLE_REQ_DSU_SFTENA — Enable sending idle request to BIU_DSU by software.
  [2] IDLE_REQ_BIGCORE1_SFTENA — Enable sending idle request to BIU_BIGCORE1 by software.
  [0] IDLE_REQ_BIGCORE0_SFTENA — Enable sending idle request to BIU_BIGCORE0 by software.
0x8078 PMU_CLUSTER_BIU_IDLE_ACK_STS — Cluster BIU idle acknowledge status register
  [4] ADB400_CORE_PACCEPT ro — PACCEPT state from core ADB400.
    0=INACTIVE; 1=ACTIVE
  [3] IDLE_ACK_LITDSU ro — BIU_LITDSU idle acknowledge state.
    0=NAK; 1=ACK
  [2] IDLE_ACK_DSU ro — BIU_DSU idle acknowledge state.
    0=NAK; 1=ACK
  [1] IDLE_ACK_BIGCORE1 ro — BIU_BIGCORE1 idle acknowledge state.
    0=NAK; 1=ACK
  [0] IDLE_ACK_BIGCORE0 ro — BIU_BIGCORE0 idle acknowledge state.
    0=NAK; 1=ACK
0x807C PMU_CLUSTER_BIU_IDLE_STS — Cluster BIU idle status register
  [4] ADB400_CORE_PACTIVE ro — PACTIVE state from core ADB400.
    0=INACTIVE; 1=ACTIVE
  [3] IDLE_LITDSU ro — BIU_LITDSU idle state.
    0=NOT_IDLE; 1=IDLE
  [2] IDLE_DSU ro — BIU_DSU idle state.
    0=NOT_IDLE; 1=IDLE
  [1] IDLE_BIGCORE1 ro — BIU_BIGCORE1 idle state.
    0=NOT_IDLE; 1=IDLE
  [0] IDLE_BIGCORE0 ro — BIU_BIGCORE0 idle state.
    0=NOT_IDLE; 1=IDLE
0x8080 PMU_CLUSTER_STS — Cluster status register
  [n+20] CPU{n}_STANDBYWFI ro (n=0..7) — CPU{n} standbywfi state.
    0=NOT (Not standbywfi); 1=STANDBY (Standbywfi)
  [19] DSU_HANDSHAKE ro — DSU P-Channel hand shake state. If P-Channel request is accepted, it is set to 1; If P-Channel request is denied, it is set to 0.
    0=NOT_HAND_SHAKE; 1=HAND_SHAKE
  [n+11] CPU{n}_HANDSHAKE ro (n=0..7) — CPU{n} P-Channel hand shake state. If P-Channel request is accepted, it is set to 1; If P-Channel request is denied, it is set to 0.
    0=NOT_HAND_SHAKE; 1=HAND_SHAKE
  [10] PD_DSU_DWN_STAT ro — VD_LITDSU power state.
    0=POWER_UP; 1=POWER_DOWN
  [9] PD_CORE1_DWN_STAT ro — VD_BIGCORE1 power state.
    0=POWER_UP; 1=POWER_DOWN
  [8] PD_CORE0_DWN_STAT ro — VD_BIGCORE0 power state.
    0=POWER_UP; 1=POWER_DOWN
  [n] PD_CPU{n}_DWN_STAT ro (n=0..7) — PD_CPU{n} power state.
    0=POWER_UP; 1=POWER_DOWN
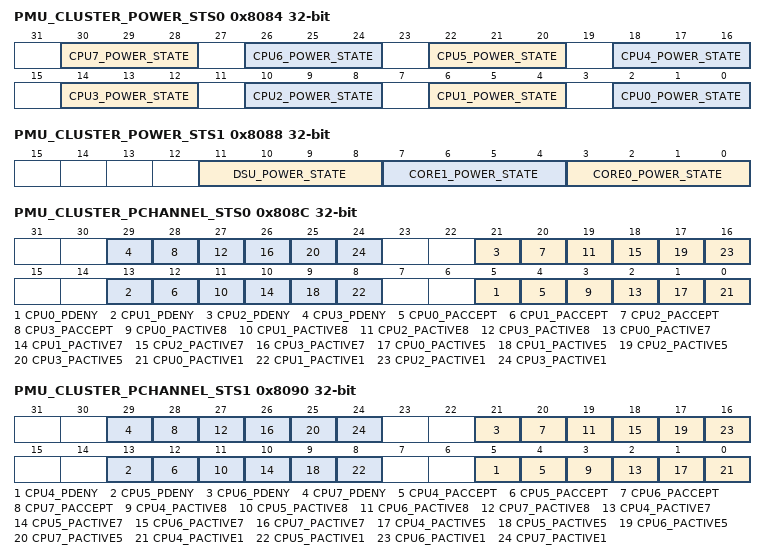
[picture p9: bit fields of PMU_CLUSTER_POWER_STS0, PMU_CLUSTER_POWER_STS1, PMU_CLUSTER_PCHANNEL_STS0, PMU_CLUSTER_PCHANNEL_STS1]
0x8084 PMU_CLUSTER_POWER_STS0 — Cluster power status register 0
  [all] fields
    0=Normal state; 1=Off state; 2=Emulated off state; 3=Retention state; 4=Debug recovery state
  [30:28] CPU7_POWER_STATE — CPU7 power state. Others: Reserved
  [4n+2:4n] CPU{n}_POWER_STATE ro (n=0..6) — CPU{n} power state. Others: Reserved
0x8088 PMU_CLUSTER_POWER_STS1 — Cluster power status register 1
  [11:8] DSU_POWER_STATE ro
    0=Normal state; 1=DSU transfer idle state; 2=DSU power down state; 3=DSU sleep state; 4=DSU wake up state; 5=DSU power up state; 6=DSU transfer resume state; 7=DSU FUNC_RET state; 8=DSU 3/4 ON state; 9=DSU 1/2 ON state; 10=DSU 1/4 ON state; 11=DSU SFONLY ON state; 12=DSU 3/4 FUNC_RET state; 13=DSU 1/2 FUNC_RET state; 14=DSU 1/4 FUNC_RET state; 15=DSU SFONLY FUNC_RET state
  [7:4] CORE1_POWER_STATE ro — BIGCORE1 power state. Others: Reserved
    0=Normal state; 1=CPU power down state; 2=Core transfer idle state; 3=Core power down state; 4=Core sleep state; 5=Core wake up state; 6=Core power up state; 7=Core transfer resume state; 8=CPU power up state
  [3:0] CORE0_POWER_STATE ro — BIGCORE0 power state. Others: Reserved
    values as CORE1_POWER_STATE
0x808C PMU_CLUSTER_PCHANNEL_STS0 — Cluster P-Channel status register 0
  [all] fields
    1=ACTIVE
  [8n+5] CPU{n}_PDENY ro (n=0..3) — CPU{n} P-Channel status.
  [8n+4] CPU{n}_PACCEPT ro (n=0..3) — CPU{n} P-Channel status.
  [8n+3] CPU{n}_PACTIVE8 ro (n=0..3) — CPU{n} P-Channel status.
  [8n+2] CPU{n}_PACTIVE7 ro (n=0..3) — CPU{n} P-Channel status.
  [8n+1] CPU{n}_PACTIVE5 ro (n=0..3) — CPU{n} P-Channel status.
  [8n] CPU{n}_PACTIVE1 ro (n=0..3) — CPU{n} P-Channel status.
0x8090 PMU_CLUSTER_PCHANNEL_STS1 — Cluster P-Channel status register 1
  [all] fields
    1=ACTIVE
  [8n-27] CPU{n}_PDENY ro (n=4..7) — CPU{n} P-Channel status.
  [8n-28] CPU{n}_PACCEPT ro (n=4..7) — CPU{n} P-Channel status.
  [8n-29] CPU{n}_PACTIVE8 ro (n=4..7) — CPU{n} P-Channel status.
  [8n-30] CPU{n}_PACTIVE7 ro (n=4..7) — CPU{n} P-Channel status.
  [8n-31] CPU{n}_PACTIVE5 ro (n=4..7) — CPU{n} P-Channel status.
  [8n-32] CPU{n}_PACTIVE1 ro (n=4..7) — CPU{n} P-Channel status.
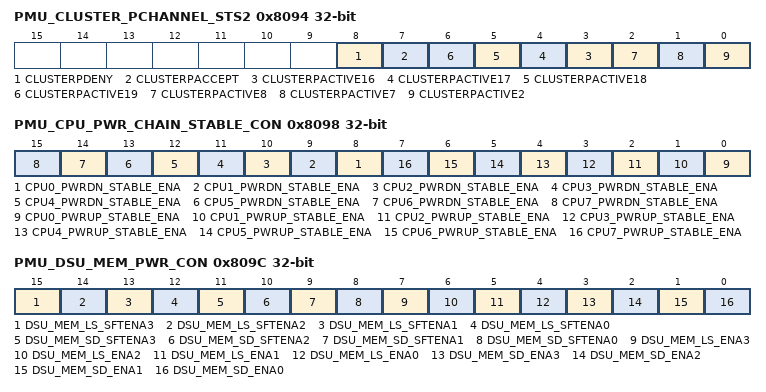
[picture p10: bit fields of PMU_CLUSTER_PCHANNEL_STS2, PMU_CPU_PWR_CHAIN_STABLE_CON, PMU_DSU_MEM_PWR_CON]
0x8094 PMU_CLUSTER_PCHANNEL_STS2 — Cluster P-Channel status register 2
  [all] fields
    1=ACTIVE
  [8] CLUSTERPDENY ro — DSU P-Channel status.
  [7] CLUSTERPACCEPT ro — DSU P-Channel status.
  [n-13] CLUSTERPACTIVE{n} ro (n=16..19) — DSU P-Channel status.
  [2] CLUSTERPACTIVE8 ro — DSU P-Channel status.
  [1] CLUSTERPACTIVE7 ro — DSU P-Channel status.
  [0] CLUSTERPACTIVE2 ro — DSU P-Channel status.
0x8098 PMU_CPU_PWR_CHAIN_STABLE_CON — CPU power chain stable control register
  [all] fields
    0=DISABLE; 1=ENABLE
  [n+8] CPU{n}_PWRDN_STABLE_ENA (n=0..7) — Enable stable counter between power chains for PD_CPU{n} power down flow.
  [n] CPU{n}_PWRUP_STABLE_ENA (n=0..7) — Enable stable counter between power chains for PD_CPU{n} power up flow.
0x809C PMU_DSU_MEM_PWR_CON — DSU memory power control register
  [all] fields
    0=DISABLE; 1=ENABLE
  [15] DSU_MEM_LS_SFTENA3 — used to light sleep "L3 Tag ways 8~11, L3 Data portion 1 RAMs".
  [14] DSU_MEM_LS_SFTENA2 — used to light sleep "L3 Tag ways 4~7".
  [13] DSU_MEM_LS_SFTENA1 — used to light sleep "L3 Tag ways 0~3, L3 Data portion 0, and L3 Victim RAMs".
  [12] DSU_MEM_LS_SFTENA0 — used to light sleep "Snoop filter and LTDB RAMs".
  [11] DSU_MEM_SD_SFTENA3 — used to shutdown "L3 Tag ways 8~11, L3 Data portion 1 RAMs".
  [10] DSU_MEM_SD_SFTENA2 — used to shutdown "L3 Tag ways 4~7".
  [9] DSU_MEM_SD_SFTENA1 — used to shutdown "L3 Tag ways 0~3, L3 Data portion 0, and L3 Victim RAMs".
  [8] DSU_MEM_SD_SFTENA0 — used to shutdown "Snoop filter and LTDB RAMs".
  [7] DSU_MEM_LS_ENA3 — used to light sleep "L3 Tag ways 8~11, L3 Data portion 1 RAMs".
  [6] DSU_MEM_LS_ENA2 — used to light sleep "L3 Tag ways 4~7".
  [5] DSU_MEM_LS_ENA1 — used to light sleep "L3 Tag ways 0~3, L3 Data portion 0, and L3 Victim RAMs".
  [4] DSU_MEM_LS_ENA0 — used to light sleep "Snoop filter and LTDB RAMs".
  [3] DSU_MEM_SD_ENA3 — used to shutdown "L3 Tag ways 8~11, L3 Data portion 1 RAMs".
  [2] DSU_MEM_SD_ENA2 — used to shutdown "L3 Tag ways 4~7".
  [1] DSU_MEM_SD_ENA1 — used to shutdown "L3 Tag ways 0~3, L3 Data portion 0, and L3 Victim RAMs".
  [0] DSU_MEM_SD_ENA0 — used to shutdown "Snoop filter and LTDB RAMs".
0x80B0 PMU_DSU_STABLE_CNT — DSU power stable count register
  [19:0] DSU_STABLE_CNT — VD_DSU power stable count. Number of clk_pmu used by counter logic.
0x80B4 PMU_DSU_PWRUP_CNT — DSU power up count register
  [19:0] DSU_PWRUP_CNT — VD_DSU power up count. Number of clk_pmu used by counter logic.
0x80B8 PMU_DSU_PWRDN_CNT — DSU power down count register
  [19:0] DSU_PWRDN_CNT — VD_DSU power down count. Number of clk_pmu used by counter logic.
0x80BC PMU_CORE0_STABLE_CNT — BIGCORE0 power stable count register
  [19:0] CORE0_STABLE_CNT — VD_BIGCORE0 power stable count. Number of clk_pmu used by counter logic.
0x80C0 PMU_CORE0_PWRUP_CNT — BIGCORE0 power up count register
  [19:0] CORE0_PWRUP_CNT — VD_BIGCORE0 power up count. Number of clk_pmu used by counter logic.
0x80C4 PMU_CORE0_PWRDN_CNT — BIGCORE0 power down count register
  [19:0] CORE0_PWRDN_CNT — VD_BIGCORE0 power down count. Number of clk_pmu used by counter logic.
0x80C8 PMU_CORE1_STABLE_CNT — BIGCORE1 power stable count register
  [19:0] CORE1_STABLE_CNT — VD_BIGCORE1 power stable count. Number of clk_pmu used by counter logic.
0x80CC PMU_CORE1_PWRUP_CNT — BIGCORE1 power up count register
  [19:0] CORE1_PWRUP_CNT — VD_BIGCORE1 power up count. Number of clk_pmu used by counter logic.
0x80D0 PMU_CORE1_PWRDN_CNT — BIGCORE1 power down count register
  [19:0] CORE1_PWRDN_CNT — VD_BIGCORE1 power down count. Number of clk_pmu used by counter logic.
{0x80D4+4i} PMU_CPU{i}_DBG_RST_CNT (i=0..7) — CPU{i} debug reset count register
  [19:0] CPU{i}_DBG_RST_CNT — CPU{i} debug reset count. Number of clk_pmu used by counter logic. The CPU reset holds low until counter to zero in debug recovery mode.
